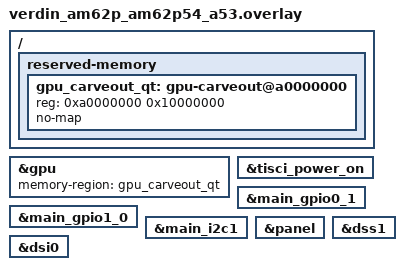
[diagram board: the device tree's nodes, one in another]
/* SPDX-License-Identifier: Apache-2.0 */
/*
 * Toradex Verdin AM62P (SafeUI board definition).  The board DTS has the
 * GPU node with its 64 MiB carveout and the display path wired but
 * disabled (the R5F owns the display in the SafeUI platform).  A Qt
 * firmware drives the panel itself, so it enables DSS1, DSI, the bridge
 * on I2C1, the GPIO banks and the TISCI power-on list -- the same set
 * the GPU driver repository's samples/zephyr/gl_slint enables.
 */

/* A 256 MiB GPU carveout instead of the board's 64 MiB one: Qt Quick 3D's
 * image based lighting (512x512 RGBA16F cube maps with their mip chains),
 * shadow maps and render targets did not fit (2026-09-17). Linux on the
 * module reserves nothing from 0xa0000000 up (OP-TEE ends there), and the
 * firmware is kexec'ed, so that DDR is ours. The board's 64 MiB region
 * stays reserved but unused. */
/ {
	reserved-memory {
		gpu_carveout_qt: gpu-carveout@a0000000 {
			reg = <0xa0000000 0x10000000>;
			no-map;
		};
	};
};

&gpu {
	memory-region = <&gpu_carveout_qt>;
};

&tisci_power_on {
	status = "okay";
};

&main_gpio0_1 {
	status = "okay";
};

&main_gpio1_0 {
	status = "okay";
};

&main_i2c1 {
	status = "okay";
};

&panel {
	status = "okay";
};

&dss1 {
	status = "okay";
};

&dsi0 {
	status = "okay";
};
